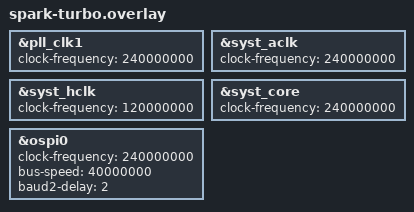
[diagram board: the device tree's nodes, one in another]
/*
 * Copyright (c) 2026 Alif Semiconductor
 * SPDX-License-Identifier: Apache-2.0
 *
 * Spark turbo clock rates changes. Applied only with: west build -S spark-turbo
 * HE PLL and ACLK at 240 MHz,
 * HCLK at 120 MHz(PLL/2), PCLK at 60 MHz(PLL/4). Default PLL is 160 MHz.
 */

&pll_clk1 {
	clock-frequency = <240000000>;
};

&syst_aclk {
	clock-frequency = <240000000>;
};

&syst_hclk {
	clock-frequency = <120000000>;
};

&syst_core {
	clock-frequency = <240000000>;
};

/*
 * OSPI SSI is ACLK. HAL writes BAUDR = clock-frequency / bus-speed.
 * TRM: BAUDR is always even (SCKDV*2, bit 0 stuck at 0).
 *   F_SCLK = F_OSPI_CLK / BAUDR,  BAUDR = 2,4,...,65534
 *
 * 80 MHz is impossible at 240 MHz: 240/80 = 3 (odd) → HW stores 2 → 120 MHz.
 * 40 MHz is even on both SSI clocks: 160/4 = 40, 240/6 = 40.
 */
&ospi0 {
	clock-frequency = <240000000>;
	bus-speed = <40000000>;
	baud2-delay = <2>;
};
